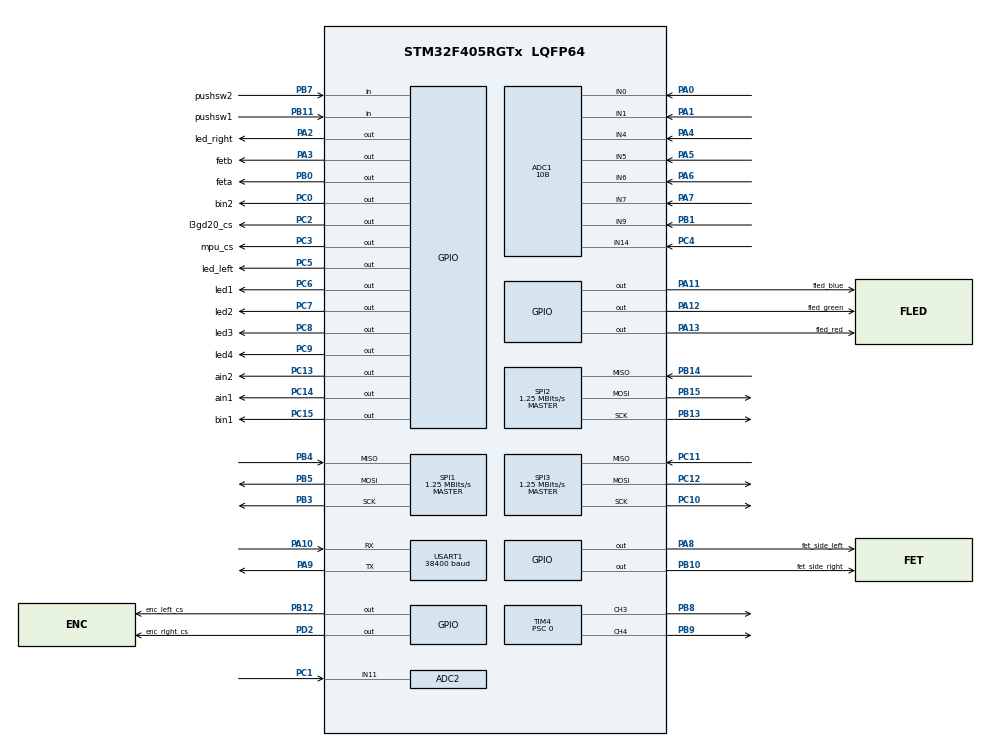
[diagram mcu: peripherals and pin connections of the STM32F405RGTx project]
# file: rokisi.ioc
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ADC1.Channel-0\#ChannelRegularConversion=ADC_CHANNEL_9
ADC1.Channel-1\#ChannelRegularConversion=ADC_CHANNEL_0
ADC1.Channel-12\#ChannelRegularConversion=ADC_CHANNEL_4
ADC1.Channel-13\#ChannelRegularConversion=ADC_CHANNEL_5
ADC1.Channel-2\#ChannelRegularConversion=ADC_CHANNEL_7
ADC1.Channel-3\#ChannelRegularConversion=ADC_CHANNEL_14
ADC1.Channel-4\#ChannelRegularConversion=ADC_CHANNEL_6
ADC1.Channel-5\#ChannelRegularConversion=ADC_CHANNEL_1
ADC1.DMAContinuousRequests=ENABLE
ADC1.NbrOfConversion=8
ADC1.NbrOfConversionFlag=1
ADC1.Rank-0\#ChannelRegularConversion=1
ADC1.Rank-1\#ChannelRegularConversion=2
ADC1.Rank-12\#ChannelRegularConversion=7
ADC1.Rank-13\#ChannelRegularConversion=8
ADC1.Rank-2\#ChannelRegularConversion=3
ADC1.Rank-3\#ChannelRegularConversion=4
ADC1.Rank-4\#ChannelRegularConversion=5
ADC1.Rank-5\#ChannelRegularConversion=6
ADC1.Resolution=ADC_RESOLUTION_10B
ADC1.SamplingTime-0\#ChannelRegularConversion=ADC_SAMPLETIME_56CYCLES
ADC1.SamplingTime-1\#ChannelRegularConversion=ADC_SAMPLETIME_56CYCLES
ADC1.SamplingTime-12\#ChannelRegularConversion=ADC_SAMPLETIME_56CYCLES
ADC1.SamplingTime-13\#ChannelRegularConversion=ADC_SAMPLETIME_56CYCLES
ADC1.SamplingTime-2\#ChannelRegularConversion=ADC_SAMPLETIME_56CYCLES
ADC1.SamplingTime-3\#ChannelRegularConversion=ADC_SAMPLETIME_56CYCLES
ADC1.SamplingTime-4\#ChannelRegularConversion=ADC_SAMPLETIME_56CYCLES
ADC1.SamplingTime-5\#ChannelRegularConversion=ADC_SAMPLETIME_56CYCLES
ADC1.ScanConvMode=ENABLE
ADC1.master=1
ADC2.Channel-8\#ChannelRegularConversion=ADC_CHANNEL_11
ADC2.ClockPrescaler=ADC_CLOCK_SYNC_PCLK_DIV4
ADC2.NbrOfConversionFlag=1
ADC2.Rank-8\#ChannelRegularConversion=1
ADC2.Resolution=ADC_RESOLUTION_10B
ADC2.SamplingTime-8\#ChannelRegularConversion=ADC_SAMPLETIME_28CYCLES
Dma.ADC1.0.Direction=DMA_PERIPH_TO_MEMORY
Dma.ADC1.0.FIFOMode=DMA_FIFOMODE_DISABLE
Dma.ADC1.0.Instance=DMA2_Stream0
Dma.ADC1.0.MemDataAlignment=DMA_MDATAALIGN_HALFWORD
Dma.ADC1.0.MemInc=DMA_MINC_ENABLE
Dma.ADC1.0.Mode=DMA_NORMAL
Dma.ADC1.0.PeriphDataAlignment=DMA_PDATAALIGN_HALFWORD
Dma.ADC1.0.PeriphInc=DMA_PINC_DISABLE
Dma.ADC1.0.Priority=DMA_PRIORITY_MEDIUM
Dma.Request0=ADC1
Mcu.Family=STM32F4
Mcu.Name=STM32F405RGTx
Mcu.Package=LQFP64
NVIC.DMA2_Stream0_IRQn=true\:0\:0\:false\:false\:true\:false\:true
NVIC.PriorityGroup=NVIC_PRIORITYGROUP_4
NVIC.TIM5_IRQn=true\:0\:0\:false\:false\:true\:true\:true
PA0-WKUP.Signal=ADCx_IN0
PA1.Signal=ADCx_IN1
PA10.Mode=Asynchronous
PA10.Signal=USART1_RX
PA11.GPIO_Label=fled_blue
PA11.Signal=GPIO_Output
PA12.GPIO_Label=fled_green
PA12.Signal=GPIO_Output
PA13.GPIO_Label=fled_red
PA13.Signal=GPIO_Output
PA2.GPIO_Label=led_right
PA2.Signal=GPIO_Output
PA3.GPIO_Label=fetb
PA3.Signal=GPIO_Output
PA4.Signal=ADCx_IN4
PA5.Signal=ADCx_IN5
PA6.Signal=ADCx_IN6
PA7.Signal=ADCx_IN7
PA8.GPIO_Label=fet_side_left
PA8.Signal=GPIO_Output
PA9.Mode=Asynchronous
PA9.Signal=USART1_TX
PB0.GPIO_Label=feta
PB0.Signal=GPIO_Output
PB1.Signal=ADCx_IN9
PB10.GPIO_Label=fet_side_right
PB10.Signal=GPIO_Output
PB11.GPIO_Label=pushsw1
PB11.Signal=GPIO_Input
PB12.GPIO_Label=enc_left_cs
PB12.Signal=GPIO_Output
PB13.Mode=Full_Duplex_Master
PB13.Signal=SPI2_SCK
PB14.Mode=Full_Duplex_Master
PB14.Signal=SPI2_MISO
PB15.Mode=Full_Duplex_Master
PB15.Signal=SPI2_MOSI
PB3.Mode=Full_Duplex_Master
PB3.Signal=SPI1_SCK
PB4.Mode=Full_Duplex_Master
PB4.Signal=SPI1_MISO
PB5.Mode=Full_Duplex_Master
PB5.Signal=SPI1_MOSI
PB7.GPIO_Label=pushsw2
PB7.Signal=GPIO_Input
PB8.Signal=S_TIM4_CH3
PB9.Signal=S_TIM4_CH4
PC0.GPIO_Label=bin2
PC0.Signal=GPIO_Output
PC1.Signal=ADCx_IN11
PC10.Mode=Full_Duplex_Master
PC10.Signal=SPI3_SCK
PC11.Mode=Full_Duplex_Master
PC11.Signal=SPI3_MISO
PC12.Mode=Full_Duplex_Master
PC12.Signal=SPI3_MOSI
PC13-ANTI_TAMP.GPIO_Label=ain2
PC13-ANTI_TAMP.Signal=GPIO_Output
PC14-OSC32_IN.GPIO_Label=ain1
PC14-OSC32_IN.Signal=GPIO_Output
PC15-OSC32_OUT.GPIO_Label=bin1
PC15-OSC32_OUT.Signal=GPIO_Output
PC2.GPIO_Label=l3gd20_cs
PC2.Signal=GPIO_Output
PC3.GPIO_Label=mpu_cs
PC3.Signal=GPIO_Output
PC4.Signal=ADCx_IN14
PC5.GPIO_Label=led_left
PC5.Signal=GPIO_Output
PC6.GPIO_Label=led1
PC6.Signal=GPIO_Output
PC7.GPIO_Label=led2
PC7.Signal=GPIO_Output
PC8.GPIO_Label=led3
PC8.Signal=GPIO_Output
PC9.GPIO_Label=led4
PC9.Signal=GPIO_Output
PD2.GPIO_Label=enc_right_cs
PD2.Signal=GPIO_Output
PH0-OSC_IN.Mode=HSE-External-Oscillator
PH0-OSC_IN.Signal=RCC_OSC_IN
PH1-OSC_OUT.Mode=HSE-External-Oscillator
PH1-OSC_OUT.Signal=RCC_OSC_OUT
ProjectManager.HeapSize=0x200
ProjectManager.StackSize=0x400
ProjectManager.TargetToolchain=Makefile
RCC.48MHZClocksFreq_Value=80000000
RCC.AHBFreq_Value=160000000
RCC.APB1CLKDivider=RCC_HCLK_DIV4
RCC.APB1Freq_Value=40000000
RCC.APB1TimFreq_Value=80000000
RCC.APB2CLKDivider=RCC_HCLK_DIV2
RCC.APB2Freq_Value=80000000
RCC.APB2TimFreq_Value=160000000
RCC.CortexFreq_Value=160000000
RCC.HCLKFreq_Value=160000000
RCC.HSE_VALUE=20000000
RCC.HSI_VALUE=16000000
RCC.LSE_VALUE=32768
RCC.PLLM=8
RCC.PLLN=160
RCC.SYSCLKFreq_VALUE=160000000
RCC.SYSCLKSource=RCC_SYSCLKSOURCE_PLLCLK
RCC.VCOOutputFreq_Value=320000000
SH.ADCx_IN0.0=ADC1_IN0,IN0
SH.ADCx_IN1.0=ADC1_IN1,IN1
SH.ADCx_IN11.0=ADC2_IN11,IN11
SH.ADCx_IN14.0=ADC1_IN14,IN14
SH.ADCx_IN4.0=ADC1_IN4,IN4
SH.ADCx_IN5.0=ADC1_IN5,IN5
SH.ADCx_IN6.0=ADC1_IN6,IN6
SH.ADCx_IN7.0=ADC1_IN7,IN7
SH.ADCx_IN9.0=ADC1_IN9,IN9
SH.S_TIM4_CH3.0=TIM4_CH3,PWM Generation3 CH3
SH.S_TIM4_CH4.0=TIM4_CH4,PWM Generation4 CH4
SPI1.BaudRatePrescaler=SPI_BAUDRATEPRESCALER_64
SPI1.CLKPhase=SPI_PHASE_2EDGE
SPI1.CLKPolarity=SPI_POLARITY_HIGH
SPI1.CalculateBaudRate=1.25 MBits/s
SPI1.Direction=SPI_DIRECTION_2LINES
SPI1.Mode=SPI_MODE_MASTER
SPI1.VirtualType=VM_MASTER
SPI2.BaudRatePrescaler=SPI_BAUDRATEPRESCALER_32
SPI2.CLKPhase=SPI_PHASE_2EDGE
SPI2.CLKPolarity=SPI_POLARITY_HIGH
SPI2.CalculateBaudRate=1.25 MBits/s
SPI2.Direction=SPI_DIRECTION_2LINES
SPI2.Mode=SPI_MODE_MASTER
SPI2.VirtualType=VM_MASTER
SPI3.BaudRatePrescaler=SPI_BAUDRATEPRESCALER_32
SPI3.CLKPhase=SPI_PHASE_2EDGE
SPI3.CLKPolarity=SPI_POLARITY_HIGH
SPI3.CalculateBaudRate=1.25 MBits/s
SPI3.Direction=SPI_DIRECTION_2LINES
SPI3.Mode=SPI_MODE_MASTER
SPI3.VirtualType=VM_MASTER
TIM4.Channel-PWM\ Generation3\ CH3=TIM_CHANNEL_3
TIM4.Channel-PWM\ Generation4\ CH4=TIM_CHANNEL_4
TIM4.Period=799
TIM4.Prescaler=0
TIM5.Period=999
TIM5.Prescaler=79
USART1.BaudRate=38400
USART1.VirtualMode=VM_ASYNC
VP_TIM5_VS_ClockSourceINT.Mode=Internal
board=custom

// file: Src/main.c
/* USER CODE BEGIN Header */
/**
  ******************************************************************************
  * @file           : main.c
  * @brief          : Main program body
  ******************************************************************************
  * @attention
  *
  * <h2><center>&copy; Copyright (c) 2020 STMicroelectronics.
  * All rights reserved.</center></h2>
  *
  * This software component is licensed by ST under BSD 3-Clause license,
  * the "License"; You may not use this file except in compliance with the
  * License. You may obtain a copy of the License at:
  *                        opensource.org/licenses/BSD-3-Clause
  *
  ******************************************************************************
  */
/* USER CODE END Header */

#include "main.h"
#include "adc.h"
#include "dma.h"
#include "spi.h"
#include "tim.h"
#include "usart.h"
#include "gpio.h"

/* USER CODE BEGIN Includes */
#include <stdio.h>

#ifdef __GNUC__
#define PUTCHAR_PROTOTYPE int __io_putchar(int ch)
#else
#define PUTCHAR_PROTOTYPE int fputc(int ch, FILE *f)
#endif /* __GNUC__ */
void __io_putchar(uint8_t ch) {
  USART1_TransmmitByte(ch);
}

#include "machine_system.h"

/* USER CODE END Includes */

void SystemClock_Config(void);

int main(void)
{

  /* MCU Configuration--------------------------------------------------------*/

  /* Reset of all peripherals, Initializes the Flash interface and the Systick. */

  LL_APB2_GRP1_EnableClock(LL_APB2_GRP1_PERIPH_SYSCFG);
  LL_APB1_GRP1_EnableClock(LL_APB1_GRP1_PERIPH_PWR);

  NVIC_SetPriorityGrouping(NVIC_PRIORITYGROUP_4);

  /* System interrupt init*/

  /* Configure the system clock */
  SystemClock_Config();

  /* Initialize all configured peripherals */
  MX_GPIO_Init();
  MX_DMA_Init();
  MX_ADC1_Init();
  MX_SPI1_Init();
  MX_SPI2_Init();
  MX_SPI3_Init();
  MX_TIM4_Init();
  MX_TIM5_Init();
  MX_USART1_UART_Init();
  MX_ADC2_Init();
  /* USER CODE BEGIN 2 */
  machine_init();
  test_case();
  /* USER CODE END 2 */

  /* Infinite loop */
  while (1)
  {

  }
}

void SystemClock_Config(void)
{
  LL_FLASH_SetLatency(LL_FLASH_LATENCY_5);

  if(LL_FLASH_GetLatency() != LL_FLASH_LATENCY_5)
  {
  Error_Handler();
  }
  LL_PWR_SetRegulVoltageScaling(LL_PWR_REGU_VOLTAGE_SCALE1);
  LL_RCC_HSI_SetCalibTrimming(16);
  LL_RCC_HSI_Enable();

   /* Wait till HSI is ready */
  while(LL_RCC_HSI_IsReady() != 1)
  {

  }
  LL_RCC_PLL_ConfigDomain_SYS(LL_RCC_PLLSOURCE_HSI, LL_RCC_PLLM_DIV_8, 160, LL_RCC_PLLP_DIV_2);
  LL_RCC_PLL_Enable();

   /* Wait till PLL is ready */
  while(LL_RCC_PLL_IsReady() != 1)
  {

  }
  LL_RCC_SetAHBPrescaler(LL_RCC_SYSCLK_DIV_1);
  LL_RCC_SetAPB1Prescaler(LL_RCC_APB1_DIV_4);
  LL_RCC_SetAPB2Prescaler(LL_RCC_APB2_DIV_2);
  LL_RCC_SetSysClkSource(LL_RCC_SYS_CLKSOURCE_PLL);

   /* Wait till System clock is ready */
  while(LL_RCC_GetSysClkSource() != LL_RCC_SYS_CLKSOURCE_STATUS_PLL)
  {

  }
  LL_Init1msTick(160000000);
  LL_SetSystemCoreClock(160000000);
}

void Error_Handler(void)
{
}

/************************ (C) COPYRIGHT STMicroelectronics *****END OF FILE****/
